# ExtScanIF_1 register map
Vendor: Texas Instruments
Peripheral module from a debugger description file (folder msp430).
Registers are 16-bit, read-write, reset 0x0 unless marked. A register's access mark holds for its fields unless they carry their own. Offsets are as the file gives them; lines under a group give offsets from that group; [hi:lo] are bit positions; {n}, {i} and the like mark numbered series; 'fields as' and 'values as' point back to an identical list; <NAME> marks a mode.

## ExtScanIF
{0xCFE+2i} ESIDEBUG{i} access not given reset not defined (i=1..5) — ESI debug register {i}
{0xD10+2i} ESICNT{i} access not given reset not defined (i=0..2) — ESI PSM counter {i}
0xD16 ESICNT3 access not given reset not defined — ESI oscillator counter register
0xD1A ESIIV access not given reset not defined — ESI interrupt vector
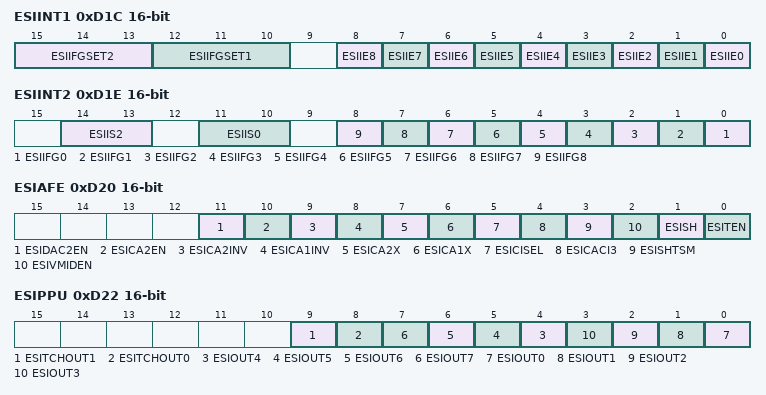
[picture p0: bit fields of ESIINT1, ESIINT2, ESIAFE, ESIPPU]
0xD1C ESIINT1 — ESI interrupt register 1
  [15:13] ESIIFGSET2 — ESIIFG8 interrupt flag source
    0=ESIIFG8 is set when ESIOUT4 is set; 1=ESIIFG8 is set when ESIOUT4 is reset; 2=ESIIFG8 is set when ESIOUT5 is set; 3=ESIIFG8 is set when ESIOUT5 is reset; 4=ESIIFG8 is set when ESIOUT6 is set; 5=ESIIFG8 is set when ESIOUT6 is reset; 6=ESIIFG8 is set when ESIOUT7 is set; 7=ESIIFG8 is set when ESIOUT7 is reset
  [12:10] ESIIFGSET1 — ESIIFG0 interrupt flag source
    0=ESIIFG0 is set when ESIOUT0 is set; 1=ESIIFG0 is set when ESIOUT0 is reset; 2=ESIIFG0 is set when ESIOUT1 is set; 3=ESIIFG0 is set when ESIOUT1 is reset; 4=ESIIFG0 is set when ESIOUT2 is set; 5=ESIIFG0 is set when ESIOUT2 is reset; 6=ESIIFG0 is set when ESIOUT3 is set; 7=ESIIFG0 is set when ESIOUT3 is reset
  [n] ESIIE{n} (n=0..8) — Interrupt enable
0xD1E ESIINT2 — ESI interrupt register 2
  [14:13] ESIIS2 — SIFIFG4 interrupt flag source
    0=SIFIFG4 interrupt flag source: SIFCNT2; 1=SIFIFG4 interrupt flag source: SIFCNT2 MOD 4; 2=SIFIFG4 interrupt flag source: SIFCNT2 MOD 256; 3=SIFIFG4 interrupt flag source: SIFCNT2 decrements from 01h to 00h
  [11:10] ESIIS0 — SIFIFG7 interrupt flag source
    0=SIFIFG7 interrupt flag source: SIFCNT0; 1=SIFIFG7 interrupt flag source: SIFCNT0 MOD 4; 2=SIFIFG7 interrupt flag source: SIFCNT0 MOD 256; 3=SIFIFG7 interrupt flag source: SIFCNT0 increments from FFFFh to 00h
  [n] ESIIFG{n} (n=0..8) — ESIIFG{n} interrupt pending
0xD20 ESIAFE — ESI AFE control register
  [11] ESIDAC2EN — Enable ESIDAC(tsm) control for DAC in AFE2
  [10] ESICA2EN — Enable ESICA(tsm) control for comparator in AFE2
  [9] ESICA2INV — Invert AFE2's comparator output
  [8] ESICA1INV — Invert AFE1's comparator output
  [7] ESICA2X — AFE2's comparator input select
  [6] ESICA1X — AFE1's comparator input select
  [5] ESICISEL — Comparator input select for AFE1 only
  [4] ESICACI3 — Comparator input select for AFE1 only
  [3] ESISHTSM — Sample-and-hold ESIVSS select
  [2] ESIVMIDEN — Mid-voltage generator
  [1] ESISH — Sample-and-hold enable
  [0] ESITEN — Excitation enable
0xD22 ESIPPU — ESI PPU control register
  [9] ESITCHOUT1 — Latched AFE1 comparator output for test channel 1
  [8] ESITCHOUT0 — Lachted AFE1 comparator output for test channel 0
  [n] ESIOUT{n} (n=4..7) — Latched AFE2 comparator output when ESICH{n-4} input is selected
  [n] ESIOUT{n} (n=0..3) — Latched AFE1 comparator output when ESICH{n} input is selected
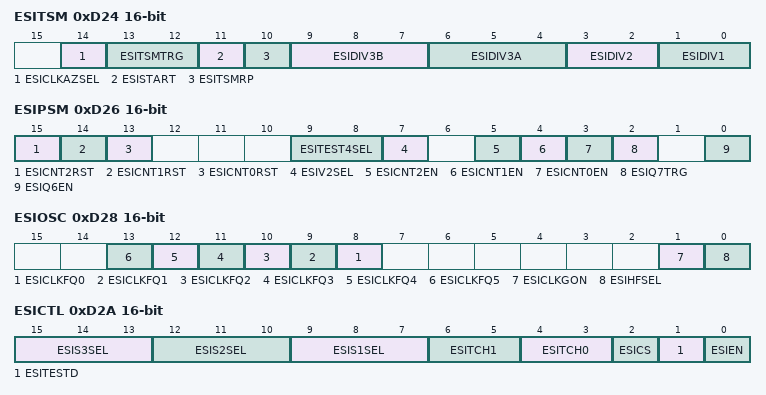
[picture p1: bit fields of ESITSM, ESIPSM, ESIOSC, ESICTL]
0xD24 ESITSM — ESI TSM control register
  [14] ESICLKAZSEL — Functionality selection of ESITSMx bit5
  [13:12] ESITSMTRG — TSM start trigger selection
    0=Halt mode; 1=TSM start trigger ACLK divider; 2=Software trigger for TSM; 3=Either the ACLK divider or the ESISTART biT
  [11] ESISTART — TSM software start trigger
  [10] ESITSMRP — TSM repeat modee
  [9:7] ESIDIV3B — TSM start trigger ACLK divider
    {v}=TSM start trigger ACLK divider (v=0..7)
  [6:4] ESIDIV3A — TSM start trigger ACLK divider
    {v}=TSM start trigger ACLK divider (v=0..7)
  [3:2] ESIDIV2 — ACLK divider
    {v}=ACLK divider mode: {v} (v=0..3)
  [1:0] ESIDIV1 — TSM SMCLK divider
    {v}=TSM SMCLK/ESIOSC divider mode: {v} (v=0..3)
0xD26 ESIPSM — ESI PSM control register
  [15] ESICNT2RST — ESI Counter 2 reset
  [14] ESICNT1RST — ESI Counter 1 reset
  [13] ESICNT0RST — ESI Counter 0 reset
  [9:8] ESITEST4SEL — Output signal selection for SIFTEST4 pin
    0=Q1 signal from PSM table; 1=Q2 signal from PSM table; 2=TSM clock signal from Timing State Machine; 3=AFE1's comparator output signal Comp1Out
  [7] ESIV2SEL — Source Selection for V2 bit
  [5] ESICNT2EN — ESICNT2 enable (down counter)
  [4] ESICNT1EN — ESICNT1 enable (up/down counter)
  [3] ESICNT0EN — ESICNT0 enable (up counter)
  [2] ESIQ7TRG — Enabling to use Q7 as trigger for a TSM sequence
  [0] ESIQ6EN — Q6 enable
0xD28 ESIOSC — ESI oscillator control register
  [n+8] ESICLKFQ{n} (n=0..5) — Internal oscillator frequency adjust
  [1] ESICLKGON — Internal oscillator control
  [0] ESIHFSEL — Internal oscillator enable
0xD2A ESICTL — ESI control register
  [15:13] ESIS3SEL — PPUS3 source select
    {v}=ESIOUT{v} is the PPUS3 source (v=0..7)
  [12:10] ESIS2SEL — PPUS2 source select
    {v}=ESIOUT{v} is the PPUS2 source (v=0..7)
  [9:7] ESIS1SEL — PPUS1 source select
    {v}=ESIOUT{v} is the PPUS1 source (v=0..7)
  [6:5] ESITCH1 — select the comparator input for test channel 1
    {v}=Comparator input is ESICH{v} when ESICAX = 0; Comparator input is ESICI{v} when ESICAX = 1 (v=0..3)
  [4:3] ESITCH0 — select the comparator input for test channel 0
    values as ESITCH1
  [2] ESICS — Comparator output/Timer_A input selection
  [1] ESITESTD — Test cycle insertion
  [0] ESIEN — Extended Scan interface enable
0xD2C ESITHR1 access not given reset not defined — ESI PSM Counter Threshold 1 register
0xD2E ESITHR2 access not given reset not defined — ESI PSM Counter Threshold 2 register
{0xD40+2i} ESIDAC1R{i} access not given reset not defined (i=0..7) — ESI DAC1 register {i}
{0xD50+2i} ESIDAC2R{i} access not given reset not defined (i=0..7) — ESI DAC2 register {i}
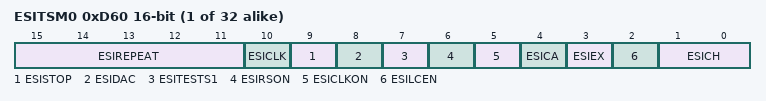
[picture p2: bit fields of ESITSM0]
{0xD60+2i} ESITSM{i} (i=0..31)
  [15:11] ESIREPEAT — These bits together with the ESICLK bit configure the duration of this state
    0=These bits configure the duration of this state; 1=ESIREPEATx selects the number of clock cycles for this state. The number of clock cycles = ESIREPEATx + 1; {v}=ESIREPEAT_{v} (v=2..31)
  [10] ESICLK — This bit selects the clock source for the TSM
  [9] ESISTOP — This bit indicates the end of the TSM sequence
  [8] ESIDAC — TSM DAC on
  [7] ESITESTS1 — TSM test cycle control
  [6] ESIRSON — Internal output latches enabled
  [5] ESICLKON — High-frequency clock on
  [4] ESICA — TSM comparator on
  [3] ESIEX — Excitation and sample-and-hold
  [2] ESILCEN — LC enable
  [1:0] ESICH — Input channel select
    {v}=Input channel select: ESICH{v} (v=0..3)
